# STM32F401x register map
File version: 1.0
CPU: CM4 r0p1, little endian, MPU, FPU, 4 interrupt priority bits
Registers are 32-bit, read-write, reset 0x0 unless marked. A register's access mark holds for its fields unless they carry their own. Offsets are from the block's base; [hi:lo] are bit positions; {n}, {i} and the like mark numbered series.

## FLASH
Base 0x40023C00
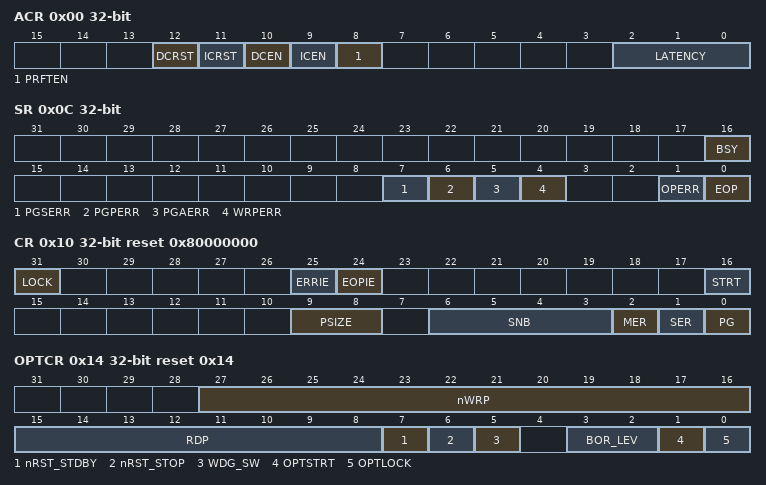
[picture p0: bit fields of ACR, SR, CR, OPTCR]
0x00 ACR access per field — Flash access control register
  [12] DCRST rw — Data cache reset
  [11] ICRST wo — Instruction cache reset
  [10] DCEN rw — Data cache enable
  [9] ICEN rw — Instruction cache enable
  [8] PRFTEN rw — Prefetch enable
  [2:0] LATENCY rw
0x04 KEYR wo — Flash key register
  [31:0] KEY — FPEC key
0x08 OPTKEYR wo — Flash option key register
  [31:0] OPTKEY — Option byte key
0x0C SR access per field — Status register
  [16] BSY ro — Busy
  [7] PGSERR rw — Programming sequence error
  [6] PGPERR rw — Programming parallelism error
  [5] PGAERR rw — Programming alignment error
  [4] WRPERR rw — Write protection error
  [1] OPERR rw — Operation error
  [0] EOP rw — End of operation
0x10 CR reset 0x80000000 — Control register
  [31] LOCK
  [25] ERRIE — Error interrupt enable
  [24] EOPIE — End of operation interrupt enable
  [16] STRT — Start
  [9:8] PSIZE — Program size
  [6:3] SNB — Sector number
  [2] MER — Mass Erase
  [1] SER — Sector Erase
  [0] PG — Programming
0x14 OPTCR reset 0x14 — Flash option control register
  [27:16] nWRP — Not write protect
  [15:8] RDP — Read protect
  [7] nRST_STDBY — nRST_STDBY User option bytes
  [6] nRST_STOP — nRST_STOP User option bytes
  [5] WDG_SW — WDG_SW User option bytes
  [3:2] BOR_LEV — BOR reset Level
  [1] OPTSTRT — Option start
  [0] OPTLOCK — Option lock

## EXTI — External interrupt/event controller
Base 0x40013C00
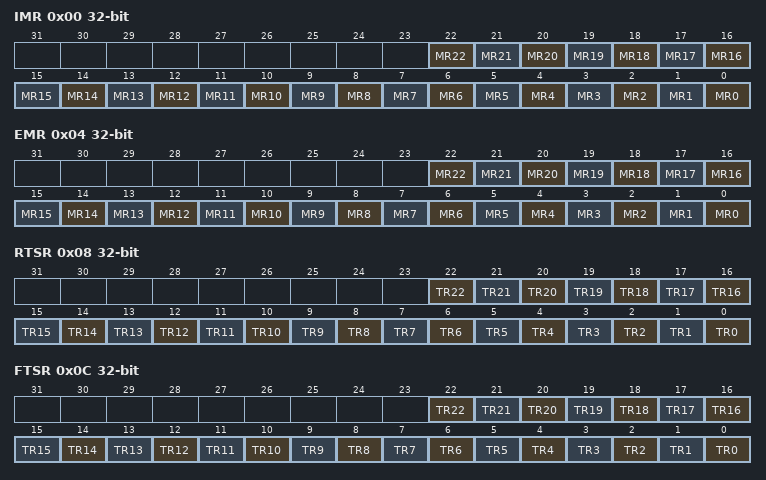
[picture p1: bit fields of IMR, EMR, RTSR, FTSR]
0x00 IMR — Interrupt mask register (EXTI_IMR)
  [n] MR{n} (n=0..22) — Interrupt Mask on line {n}
0x04 EMR — Event mask register (EXTI_EMR)
  [n] MR{n} (n=0..22) — Event Mask on line {n}
0x08 RTSR — Rising Trigger selection register (EXTI_RTSR)
  [n] TR{n} (n=0..22) — Rising trigger event configuration of line {n}
0x0C FTSR — Falling Trigger selection register (EXTI_FTSR)
  [n] TR{n} (n=0..22) — Falling trigger event configuration of line {n}
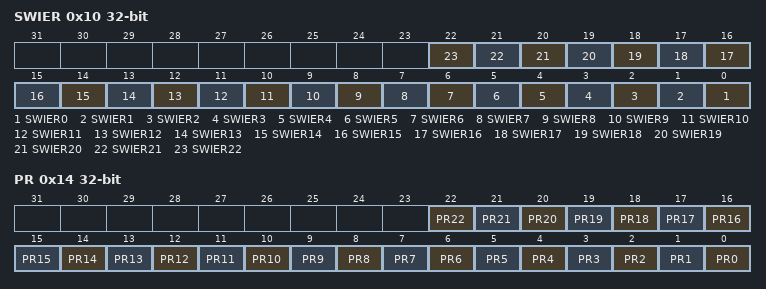
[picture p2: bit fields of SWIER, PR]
0x10 SWIER — Software interrupt event register (EXTI_SWIER)
  [n] SWIER{n} (n=0..22) — Software Interrupt on line {n}
0x14 PR — Pending register (EXTI_PR)
  [n] PR{n} (n=0..22) — Pending bit {n}

## NVIC — Nested Vectored Interrupt Controller
Base 0xE000E000
0x04 ICTR ro — Interrupt Controller Type Register
  [3:0] INTLINESNUM — Total number of interrupt lines in groups
{0x100+4i} ISER{i} (i=0..2) — Interrupt Set-Enable Register
  [31:0] SETENA
{0x180+4i} ICER{i} (i=0..2) — Interrupt Clear-Enable Register
  [31:0] CLRENA
{0x200+4i} ISPR{i} (i=0..2) — Interrupt Set-Pending Register
  [31:0] SETPEND
{0x280+4i} ICPR{i} (i=0..2) — Interrupt Clear-Pending Register
  [31:0] CLRPEND
{0x300+4i} IABR{i} ro (i=0..2) — Interrupt Active Bit Register
  [31:0] ACTIVE
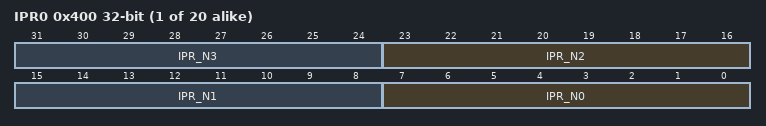
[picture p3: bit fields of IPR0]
{0x400+4i} IPR{i} (i=0..19) — Interrupt Priority Register
  [8n+7:8n] IPR_N{n} (n=0..3)
0xF00 STIR wo — Software Triggered Interrupt Register
  [8:0] INTID — interrupt to be triggered

## ADC_Common — ADC common registers
Base 0x40012300
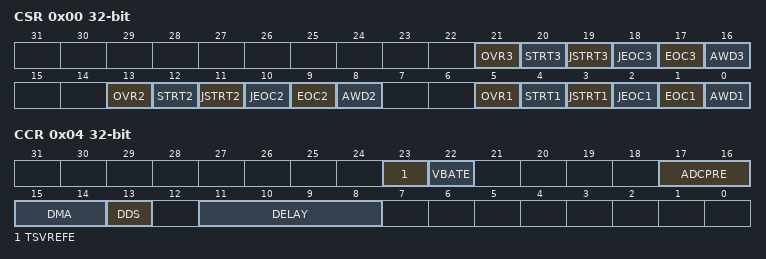
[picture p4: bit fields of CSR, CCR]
0x00 CSR ro — ADC Common status register
  [21] OVR3 — Overrun flag of ADC3
  [20] STRT3 — Regular channel Start flag of ADC 3
  [19] JSTRT3 — Injected channel Start flag of ADC 3
  [18] JEOC3 — Injected channel end of conversion of ADC 3
  [17] EOC3 — End of conversion of ADC 3
  [16] AWD3 — Analog watchdog flag of ADC 3
  [13] OVR2 — Overrun flag of ADC 2
  [12] STRT2 — Regular channel Start flag of ADC 2
  [11] JSTRT2 — Injected channel Start flag of ADC 2
  [10] JEOC2 — Injected channel end of conversion of ADC 2
  [9] EOC2 — End of conversion of ADC 2
  [8] AWD2 — Analog watchdog flag of ADC 2
  [5] OVR1 — Overrun flag of ADC 1
  [4] STRT1 — Regular channel Start flag of ADC 1
  [3] JSTRT1 — Injected channel Start flag of ADC 1
  [2] JEOC1 — Injected channel end of conversion of ADC 1
  [1] EOC1 — End of conversion of ADC 1
  [0] AWD1 — Analog watchdog flag of ADC 1
0x04 CCR — ADC common control register
  [23] TSVREFE — Temperature sensor and VREFINT enable
  [22] VBATE — VBAT enable
  [17:16] ADCPRE — ADC prescaler
  [15:14] DMA — Direct memory access mode for multi ADC mode
  [13] DDS — DMA disable selection for multi-ADC mode
  [11:8] DELAY — Delay between 2 sampling phases

## FPU — Floting point unit
Base 0xE000EF34
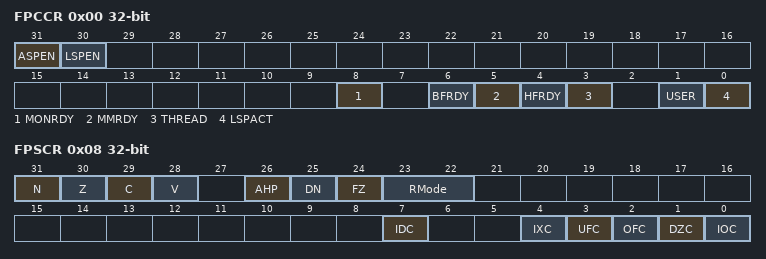
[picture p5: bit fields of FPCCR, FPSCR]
0x00 FPCCR — Floating-point context control register
  [31] ASPEN, [30] LSPEN, [8] MONRDY, [6] BFRDY, [5] MMRDY, [4] HFRDY, [3] THREAD, [1] USER, [0] LSPACT
0x04 FPCAR — Floating-point context address register
  [31:3] ADDRESS — Location of unpopulated floating-point
0x08 FPSCR — Floating-point status control register
  [31] N — Negative condition code flag
  [30] Z — Zero condition code flag
  [29] C — Carry condition code flag
  [28] V — Overflow condition code flag
  [26] AHP — Alternative half-precision control bit
  [25] DN — Default NaN mode control bit
  [24] FZ — Flush-to-zero mode control bit:
  [23:22] RMode — Rounding Mode control field
  [7] IDC — Input denormal cumulative exception bit.
  [4] IXC — Inexact cumulative exception bit
  [3] UFC — Underflow cumulative exception bit
  [2] OFC — Overflow cumulative exception bit
  [1] DZC — Division by zero cumulative exception bit.
  [0] IOC — Invalid operation cumulative exception bit

## MPU — Memory protection unit
Base 0xE000ED90
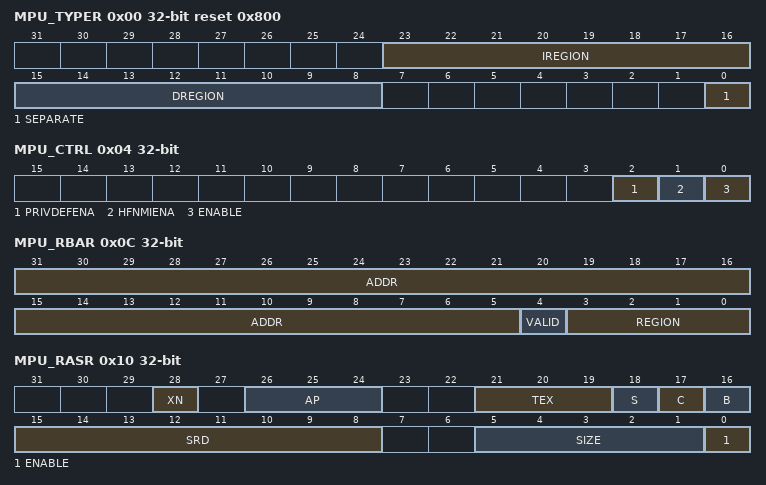
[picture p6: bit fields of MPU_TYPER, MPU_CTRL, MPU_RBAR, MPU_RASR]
0x00 MPU_TYPER ro reset 0x800 — MPU type register
  [23:16] IREGION — Number of MPU instruction regions
  [15:8] DREGION — Number of MPU data regions
  [0] SEPARATE — Separate flag
0x04 MPU_CTRL ro — MPU control register
  [2] PRIVDEFENA — Enable priviliged software access to default memory map
  [1] HFNMIENA — Enables the operation of MPU during hard fault
  [0] ENABLE — Enables the MPU
0x08 MPU_RNR — MPU region number register
  [7:0] REGION — MPU region
0x0C MPU_RBAR — MPU region base address register
  [31:5] ADDR — Region base address field
  [4] VALID — MPU region number valid
  [3:0] REGION — MPU region field
0x10 MPU_RASR — MPU region attribute and size register
  [28] XN — Instruction access disable bit
  [26:24] AP — Access permission
  [21:19] TEX — memory attribute
  [18] S — Shareable memory attribute
  [17] C — memory attribute
  [16] B — memory attribute
  [15:8] SRD — Subregion disable bits
  [5:1] SIZE — Size of the MPU protection region
  [0] ENABLE — Region enable bit.

## STK — SysTick timer
Base 0xE000E010
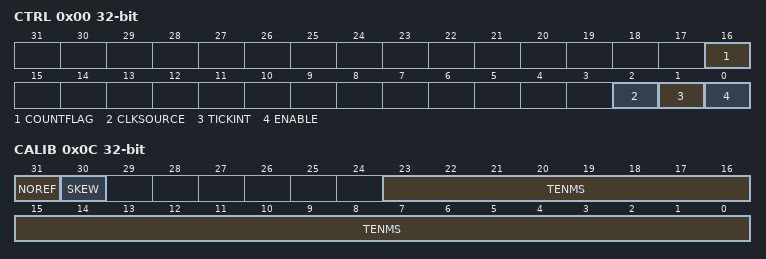
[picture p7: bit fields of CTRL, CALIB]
0x00 CTRL — SysTick control and status register
  [16] COUNTFLAG
  [2] CLKSOURCE — Clock source selection
  [1] TICKINT — SysTick exception request enable
  [0] ENABLE — Counter enable
0x04 LOAD — SysTick reload value register
  [23:0] RELOAD — RELOAD value
0x08 VAL — SysTick current value register
  [23:0] CURRENT — Current counter value
0x0C CALIB — SysTick calibration value register
  [31] NOREF — NOREF flag. Reads as zero
  [30] SKEW — SKEW flag: Indicates whether the TENMS value is exact
  [23:0] TENMS — Calibration value
